# CH32V30xxx register map
Vendor: WCH Ltd.; File version: 1.0
Registers are 32-bit, read-write, reset 0x0 unless marked. A register's access mark holds for its fields unless they carry their own. Offsets are from the block's base; [hi:lo] are bit positions; {n}, {i} and the like mark numbered series.

## OPA — OPA configuration
Base 0x40023804
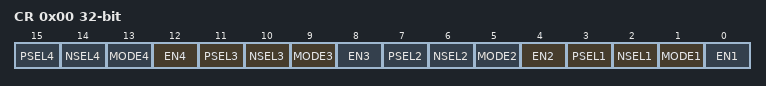
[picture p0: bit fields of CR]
0x00 CR — Control register
  [4n-1] PSEL{n} (n=1..4) — OPA PSEL{n}
  [4n-2] NSEL{n} (n=1..4) — OPA NSEL{n}
  [4n-3] MODE{n} (n=1..4) — OPA MODE{n}
  [12] EN4 — OPA Enable4
  [8] EN3 — OPA Eable3
  [4] EN2 — OPA Enable2
  [0] EN1 — OPA Enable1

## GPIOA — General purpose I/O
Base 0x40010800
Same registers: GPIOB 0x40010C00, GPIOC 0x40011000, GPIOD 0x40011400, GPIOE 0x40011800
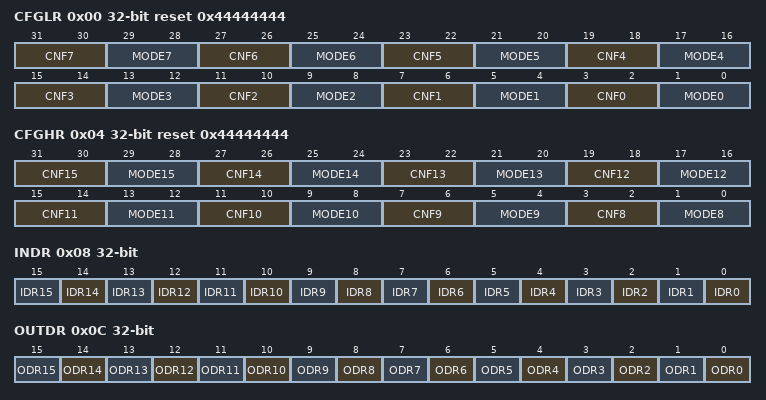
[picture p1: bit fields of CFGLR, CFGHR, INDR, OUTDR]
0x00 CFGLR reset 0x44444444 — Port configuration register low (GPIOn_CFGLR)
  [31:30] CNF7 — Port n.7 configuration bits
  [29:28] MODE7 — Port n.7 mode bits
  [27:26] CNF6 — Port n.6 configuration bits
  [25:24] MODE6 — Port n.6 mode bits
  [23:22] CNF5 — Port n.5 configuration bits
  [21:20] MODE5 — Port n.5 mode bits
  [19:18] CNF4 — Port n.4 configuration bits
  [17:16] MODE4 — Port n.4 mode bits
  [15:14] CNF3 — Port n.3 configuration bits
  [13:12] MODE3 — Port n.3 mode bits
  [11:10] CNF2 — Port n.2 configuration bits
  [9:8] MODE2 — Port n.2 mode bits
  [7:6] CNF1 — Port n.1 configuration bits
  [5:4] MODE1 — Port n.1 mode bits
  [3:2] CNF0 — Port n.0 configuration bits
  [1:0] MODE0 — Port n.0 mode bits
0x04 CFGHR reset 0x44444444 — Port configuration register high (GPIOn_CFGHR)
  [31:30] CNF15 — Port n.15 configuration bits
  [29:28] MODE15 — Port n.15 mode bits
  [27:26] CNF14 — Port n.14 configuration bits
  [25:24] MODE14 — Port n.14 mode bits
  [23:22] CNF13 — Port n.13 configuration bits
  [21:20] MODE13 — Port n.13 mode bits
  [19:18] CNF12 — Port n.12 configuration bits
  [17:16] MODE12 — Port n.12 mode bits
  [15:14] CNF11 — Port n.11 configuration bits
  [13:12] MODE11 — Port n.11 mode bits
  [11:10] CNF10 — Port n.10 configuration bits
  [9:8] MODE10 — Port n.10 mode bits
  [7:6] CNF9 — Port n.9 configuration bits
  [5:4] MODE9 — Port n.9 mode bits
  [3:2] CNF8 — Port n.8 configuration bits
  [1:0] MODE8 — Port n.8 mode bits
0x08 INDR ro — Port input data register (GPIOn_INDR)
  [n] IDR{n} (n=0..15) — Port input data
0x0C OUTDR — Port output data register (GPIOn_OUTDR)
  [n] ODR{n} (n=0..15) — Port output data
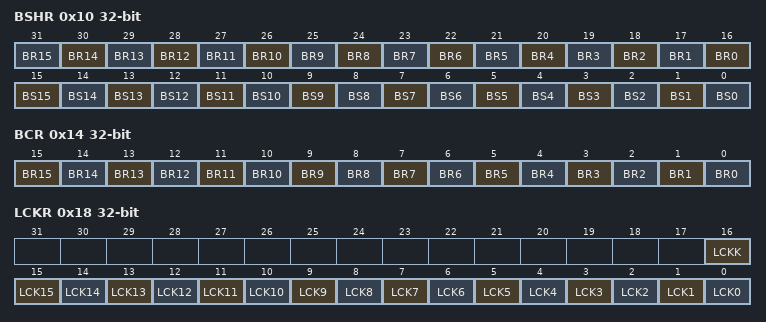
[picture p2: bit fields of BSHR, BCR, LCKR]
0x10 BSHR wo — Port bit set/reset register (GPIOn_BSHR)
  [n+16] BR{n} (n=0..15) — Reset bit {n}
  [n] BS{n} (n=3..15) — Set bit {n}
  [2] BS2 — Set bit 1
  [1] BS1 — Set bit 1
  [0] BS0 — Set bit 0
0x14 BCR wo — Port bit reset register (GPIOn_BCR)
  [n] BR{n} (n=3..15) — Reset bit {n}
  [2] BR2 — Reset bit 1
  [1] BR1 — Reset bit 1
  [0] BR0 — Reset bit 0
0x18 LCKR — Port configuration lock register
  [16] LCKK — Lock key
  [n] LCK{n} (n=0..15) — Port A Lock bit {n}

## AFIO — Alternate function I/O
Base 0x40010000
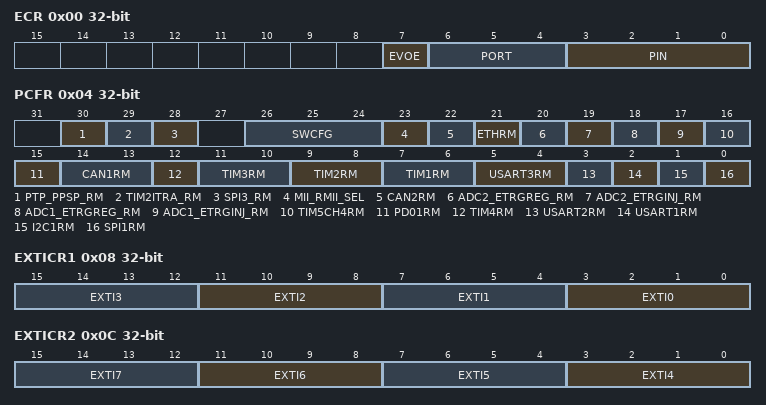
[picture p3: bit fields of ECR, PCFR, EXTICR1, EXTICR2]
0x00 ECR — Event Control Register (AFIO_ECR)
  [7] EVOE — Event Output Enable
  [6:4] PORT — Port selection
  [3:0] PIN — Pin selection
0x04 PCFR access per field — AF remap and debug I/O configuration register (AFIO_PCFR)
  [30] PTP_PPSP_RM rw — Ethernet PTP_PPS remapping
  [29] TIM2ITRA_RM rw — TIM2 internally triggers 1 remapping
  [28] SPI3_RM rw — SPI3 remapping
  [26:24] SWCFG wo — Serial wire JTAG configuration
  [23] MII_RMII_SEL rw
  [22] CAN2RM rw — CAN2 remapping
  [21] ETHRM rw — Ethernet remapping
  [20] ADC2_ETRGREG_RM rw — ADC 2 external trigger regular conversion remapping
  [19] ADC2_ETRGINJ_RM rw — ADC 2 External trigger injected conversion remapping
  [18] ADC1_ETRGREG_RM rw — ADC 1 external trigger regular conversion remapping
  [17] ADC1_ETRGINJ_RM rw — ADC 1 External trigger injected conversion remapping
  [16] TIM5CH4RM rw — TIM5 channel4 internal remap
  [15] PD01RM rw — Port D0/Port D1 mapping on OSCIN/OSCOUT
  [14:13] CAN1RM rw — CAN1 remapping
  [12] TIM4RM rw — TIM4 remapping
  [11:10] TIM3RM rw — TIM3 remapping
  [9:8] TIM2RM rw — TIM2 remapping
  [7:6] TIM1RM rw — TIM1 remapping
  [5:4] USART3RM rw — USART3 remapping
  [3] USART2RM rw — USART2 remapping
  [2] USART1RM rw — USART1 remapping
  [1] I2C1RM rw — I2C1 remapping
  [0] SPI1RM rw — SPI1 remapping
0x08 EXTICR1 — External interrupt configuration register 1 (AFIO_EXTICR1)
  [4n+3:4n] EXTI{n} (n=0..3) — EXTI{n} configuration
0x0C EXTICR2 — External interrupt configuration register 2 (AFIO_EXTICR2)
  [4n-13:4n-16] EXTI{n} (n=4..7) — EXTI{n} configuration
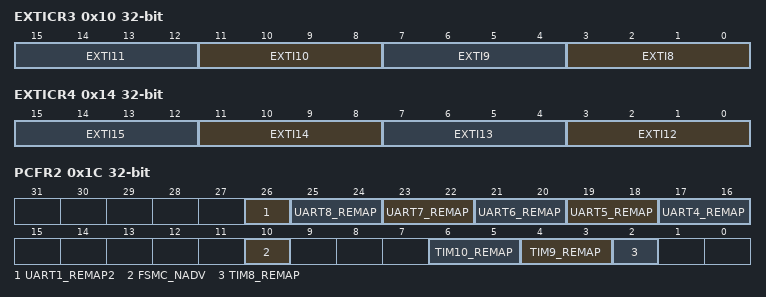
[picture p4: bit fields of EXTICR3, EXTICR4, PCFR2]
0x10 EXTICR3 — External interrupt configuration register 3 (AFIO_EXTICR3)
  [4n-29:4n-32] EXTI{n} (n=8..11) — EXTI{n} configuration
0x14 EXTICR4 — External interrupt configuration register 4 (AFIO_EXTICR4)
  [4n-45:4n-48] EXTI{n} (n=12..15) — EXTI{n} configuration
0x1C PCFR2 — AF remap and debug I/O configuration register (AFIO_PCFR2)
  [26] UART1_REMAP2 — UART1 remapping
  [2n+9:2n+8] UART{n}_REMAP (n=4..8) — UART{n} remapping
  [10] FSMC_NADV
  [6:5] TIM10_REMAP — TIM10 remapping
  [4:3] TIM9_REMAP — TIM9 remapping
  [2] TIM8_REMAP — TIM8 remapping
